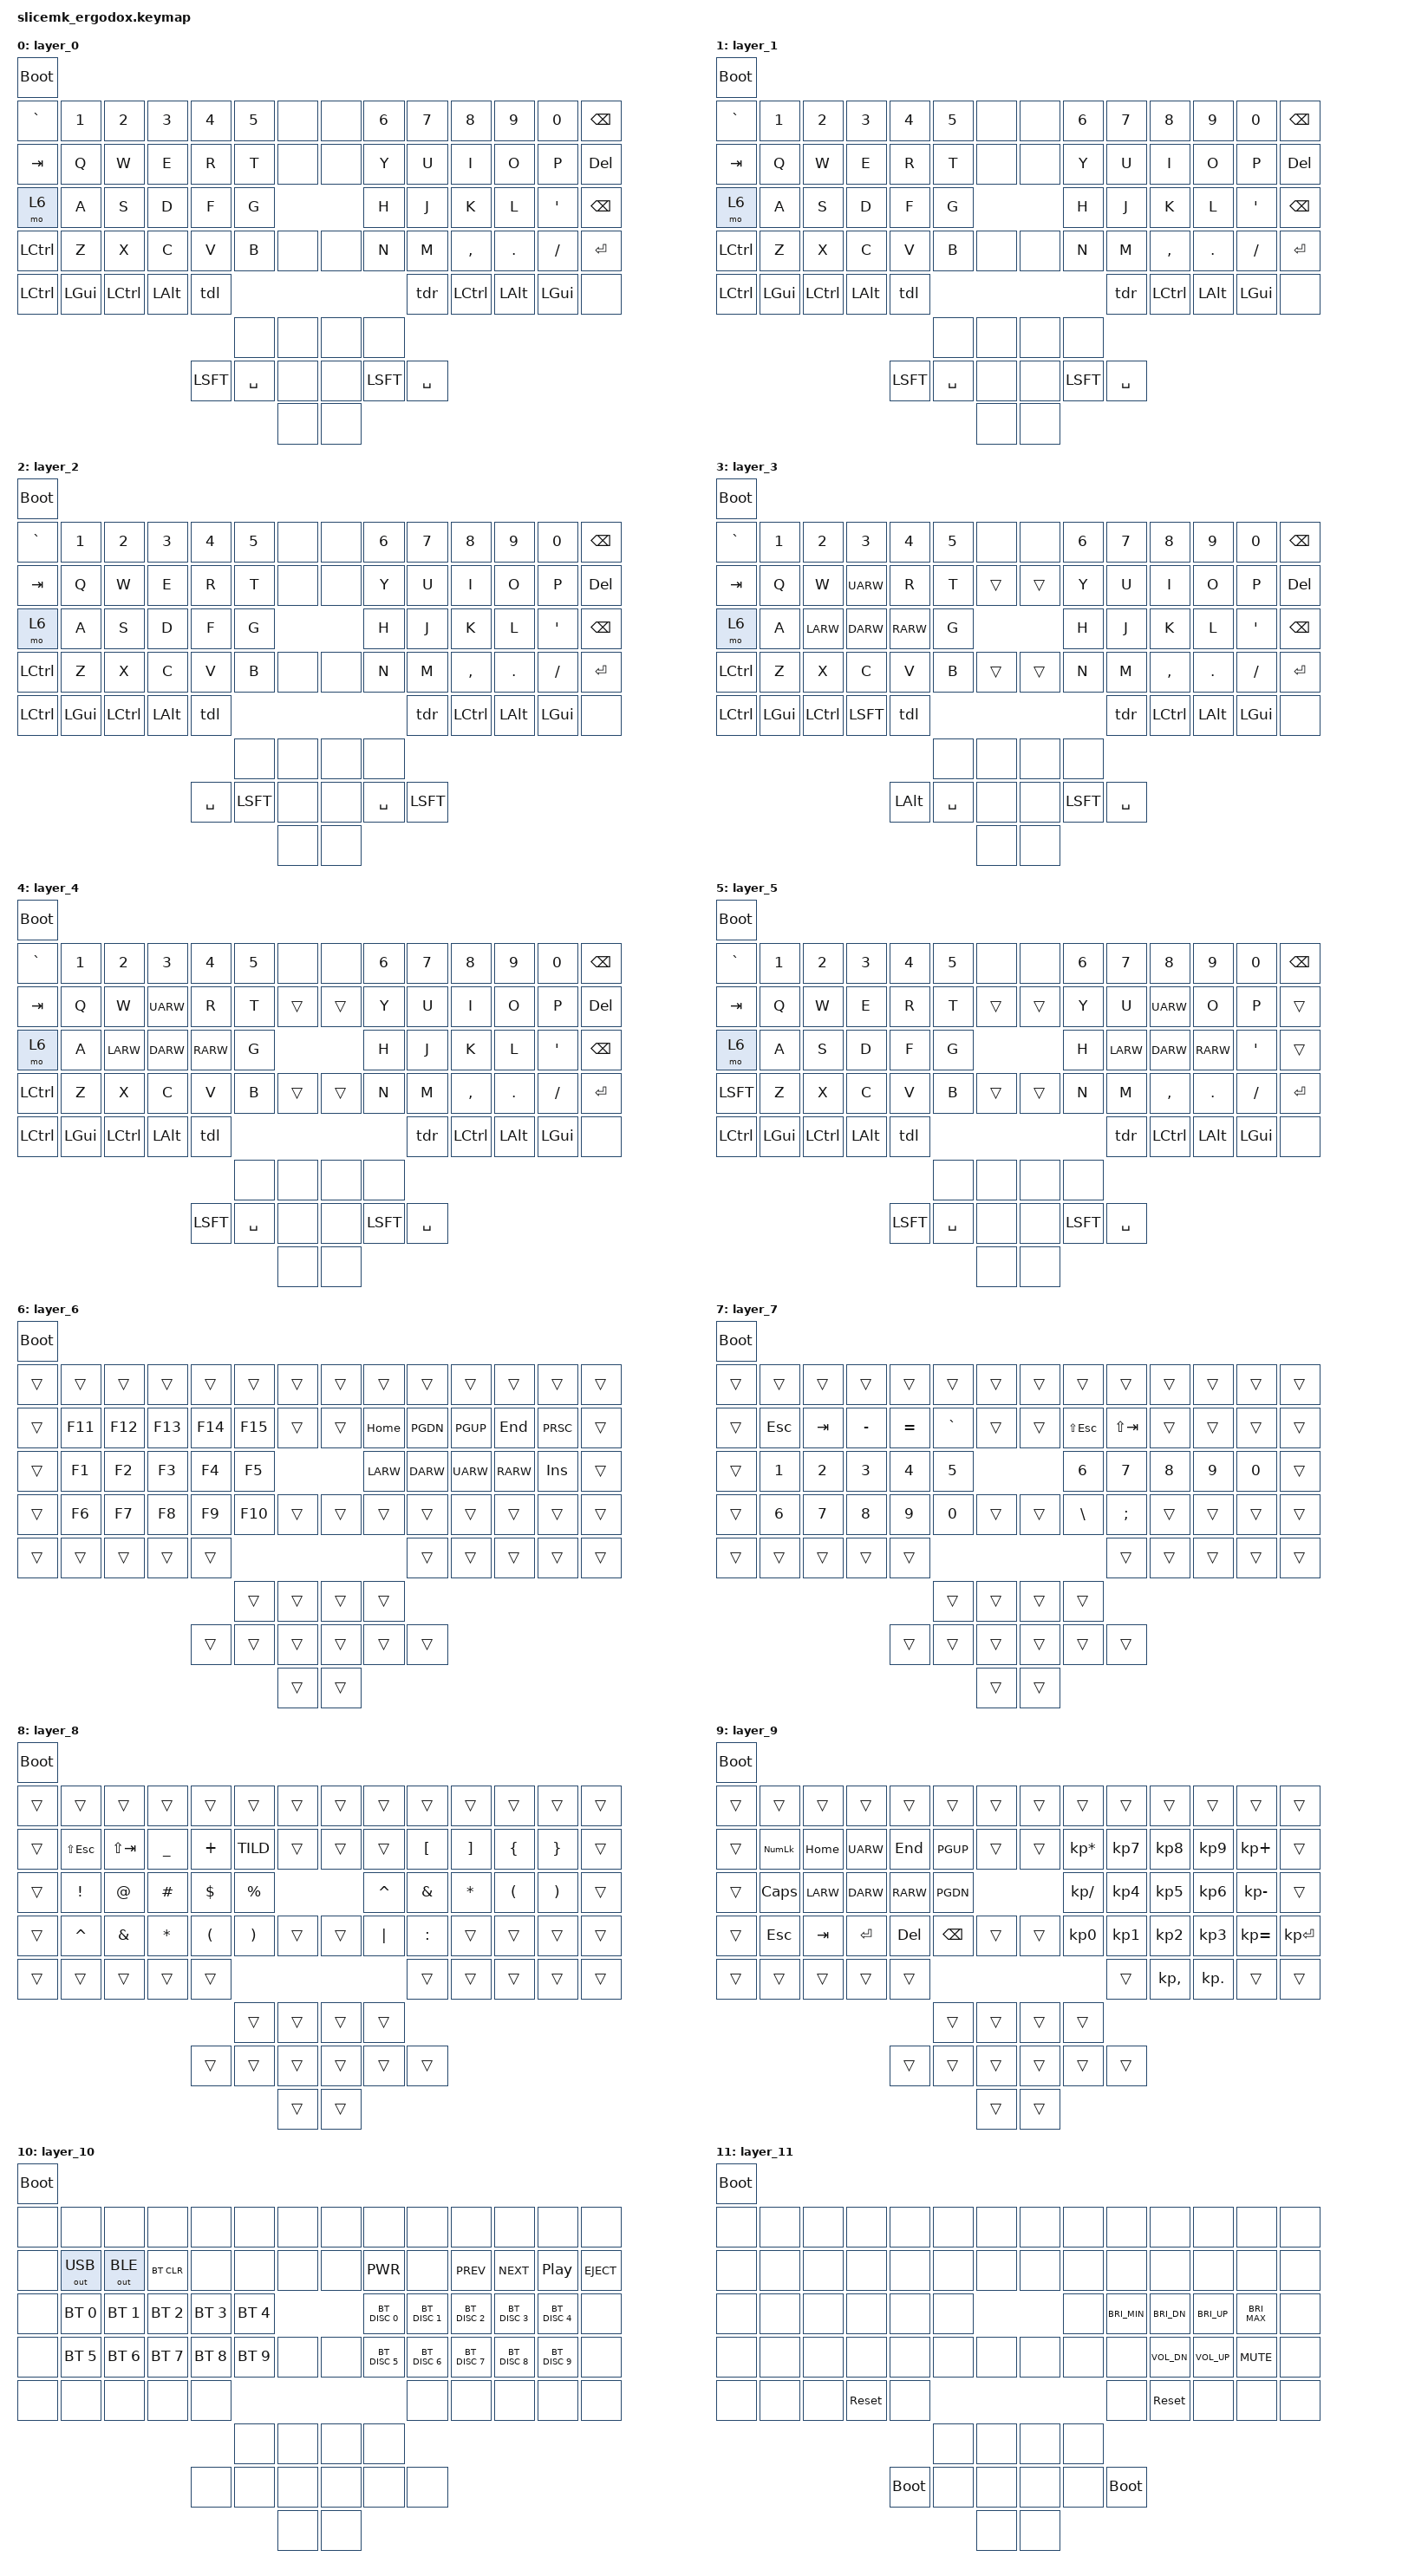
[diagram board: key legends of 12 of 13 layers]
#include <behaviors.dtsi>
#include <dt-bindings/zmk/bt.h>
#include <dt-bindings/zmk/keys.h>
#include <dt-bindings/zmk/outputs.h>

/ {
    combos {
        compatible = "zmk,combos";
        combo_func {
            timeout-ms = <35>;
            key-positions = <59 30>;
            bindings = <&mo 5>;
            slow-release;
        };
        combo_lctl_lower {
            timeout-ms = <35>;
            key-positions = <59 42>;
            bindings = <&kp LCTL>;
            slow-release;
        };
        combo_lshift_lctl {
            timeout-ms = <35>;
            key-positions = <42 60>;
            bindings = <&kp LS(LCTL)>;
            slow-release;
        };
        combo_rshift_rctl {
            timeout-ms = <35>;
            key-positions = <59 61>;
            bindings = <&kp RS(RCTL)>;
            slow-release;
        };
        combo_ralt_raise {
            timeout-ms = <35>;
            key-positions = <60 53>;
            bindings = <&kp RALT>;
            slow-release;
        };
        combo_lshift_lalt {
            timeout-ms = <35>;
            key-positions = <58 60>;
            bindings = <&kp LS(LALT)>;
            slow-release;
        };
        combo_rshift_ralt {
            timeout-ms = <35>;
            key-positions = <59 53>;
            bindings = <&kp RS(RALT)>;
            slow-release;
        };
        combo_lgui_lower {
            timeout-ms = <35>;
            key-positions = <46 59>;
            bindings = <&kp LGUI>;
            slow-release;
        };
        combo_rgui_raise {
            timeout-ms = <35>;
            key-positions = <49 60>;
            bindings = <&kp RS(RGUI)>;
            slow-release;
        };
        combo_ralt {
            timeout-ms = <35>;
            key-positions = <53 60>;
            bindings = <&kp RALT>;
            slow-release;
        };
        combo_lgui {
            timeout-ms = <35>;
            key-positions = <45 46>;
            bindings = <&kp LGUI>;
            layers = <0 6 7 8 9>;
            slow-release;
        };
        combo_rgui {
            timeout-ms = <35>;
            key-positions = <49 50>;
            bindings = <&kp RS(RGUI)>;
            layers = <0 6 7 8 9>;
            slow-release;
        };
        combo_lctl_lalt {
            timeout-ms = <35>;
            key-positions = <42 58>;
            bindings = <&kp LC(LALT)>;
            slow-release;
        };
        combo_rctl_ralt {
            timeout-ms = <35>;
            key-positions = <61 53>;
            bindings = <&kp RC(RALT)>;
            slow-release;
        };
        combo_lalt_tab {
            timeout-ms = <35>;
            key-positions = <16 58>;
            bindings = <&kp LA(TAB)>;
            slow-release;
        };
        combo_lgui_tab {
            timeout-ms = <35>;
            key-positions = <34 46>;
            bindings = <&kp LG(TAB)>;
            slow-release;
        };
        combo_rshift_rgui_tab {
            timeout-ms = <35>;
            key-positions = <35 49>;
            bindings = <&kp RS(RG(TAB))>;
            slow-release;
        };
        combo_layers {
            timeout-ms = <35>;
            key-positions = <59 60>;
            bindings = <&mo 12>;
        };
    };
    behaviors {
        tdl: tap_dance_l {
            compatible = "zmk,behavior-tap-dance";
            label = "TAP_DANCE_L";
            #binding-cells = <0>;
            tapping-term-ms = <400>;
            bindings = <&mo 7>, <&mo 6>, <&mo 10>;
        };
        tdr: tap_dance_r {
            compatible = "zmk,behavior-tap-dance";
            label = "TAP_DANCE_R";
            #binding-cells = <0>;
            tapping-term-ms = <400>;
            bindings = <&mo 8>, <&mo 6>, <&mo 11>;
        };
    };
};

/ {
	keymap {
		compatible = "zmk,keymap";

//				0
//				1  2  3  4  5  6  7  8  9  10 11 12 13 14
//				15 16 17 18 19 20 21 22 23 24 25 26 27 28
//				29 30 31 32 33 34       35 36 37 38 39 40
//				41 42 43 44 45 46 47 48 49 50 51 52 53 54
//				55 56 57 58 59             60 61 62 63 64
//				               65 66 67 68
//				            69 70 71 72 73 74
//				                  75 76

		layer_0 {
			bindings = <
				&bootloader
				&kp GRAV &kp NUMBER_1 &kp NUMBER_2 &kp NUMBER_3 &kp NUMBER_4 &kp NUMBER_5 &none &none &kp NUMBER_6 &kp NUMBER_7 &kp NUMBER_8 &kp NUMBER_9 &kp NUMBER_0 &kp BKSP
				&kp TAB  &kp Q        &kp W        &kp E        &kp R        &kp T        &none &none &kp Y        &kp U        &kp I        &kp O        &kp P        &kp DEL
				&mo 6    &kp A        &kp S        &kp D        &kp F        &kp G                    &kp H        &kp J        &kp K        &kp L        &kp SQT      &kp BKSP
				&kp LCTL &kp Z        &kp X        &kp C        &kp V        &kp B        &none &none &kp N        &kp M        &kp CMMA     &kp DOT      &kp FSLH     &kp RET
				&kp LCTL &kp LGUI     &kp LCTL     &kp LALT     &tdl                                               &tdr         &kp LCTL     &kp LALT     &kp LGUI     &none
				                                                             &none        &none &none &none
				                                                &kp LSFT     &kp SPC      &none &none &kp LSFT     &kp SPC
				                                                                          &none &none
			>;
		};

		layer_1 {
			bindings = <
				&bootloader
				&kp GRAV &kp NUMBER_1 &kp NUMBER_2 &kp NUMBER_3 &kp NUMBER_4 &kp NUMBER_5 &none &none &kp NUMBER_6 &kp NUMBER_7 &kp NUMBER_8 &kp NUMBER_9 &kp NUMBER_0 &kp BKSP
				&kp TAB  &kp Q        &kp W        &kp E        &kp R        &kp T        &none &none &kp Y        &kp U        &kp I        &kp O        &kp P        &kp DEL
				&mo 6    &kp A        &kp S        &kp D        &kp F        &kp G                    &kp H        &kp J        &kp K        &kp L        &kp SQT      &kp BKSP
				&kp LCTL &kp Z        &kp X        &kp C        &kp V        &kp B        &none &none &kp N        &kp M        &kp CMMA     &kp DOT      &kp FSLH     &kp RET
				&kp LCTL &kp LGUI     &kp LCTL     &kp LALT     &tdl                                               &tdr         &kp LCTL     &kp LALT     &kp LGUI     &none
				                                                             &none        &none &none &none
				                                                &kp LSFT     &kp SPC      &none &none &kp LSFT     &kp SPC
				                                                                          &none &none
			>;
		};

		layer_2 {
			bindings = <
				&bootloader
				&kp GRAV &kp NUMBER_1 &kp NUMBER_2 &kp NUMBER_3 &kp NUMBER_4 &kp NUMBER_5 &none &none &kp NUMBER_6 &kp NUMBER_7 &kp NUMBER_8 &kp NUMBER_9 &kp NUMBER_0 &kp BKSP
				&kp TAB  &kp Q        &kp W        &kp E        &kp R        &kp T        &none &none &kp Y        &kp U        &kp I        &kp O        &kp P        &kp DEL
				&mo 6    &kp A        &kp S        &kp D        &kp F        &kp G                    &kp H        &kp J        &kp K        &kp L        &kp SQT      &kp BKSP
				&kp LCTL &kp Z        &kp X        &kp C        &kp V        &kp B        &none &none &kp N        &kp M        &kp CMMA     &kp DOT      &kp FSLH     &kp RET
				&kp LCTL &kp LGUI     &kp LCTL     &kp LALT     &tdl                                               &tdr         &kp LCTL     &kp LALT     &kp LGUI     &none
				                                                             &none        &none &none &none
				                                                &kp SPC      &kp LSFT     &none &none &kp SPC      &kp LSFT
				                                                                          &none &none
			>;
		};

		layer_3 {
			bindings = <
				&bootloader
				&kp GRAV &kp NUMBER_1 &kp NUMBER_2 &kp NUMBER_3 &kp NUMBER_4 &kp NUMBER_5 &none  &none  &kp NUMBER_6 &kp NUMBER_7 &kp NUMBER_8 &kp NUMBER_9 &kp NUMBER_0 &kp BKSP
				&kp TAB  &kp Q        &kp W        &kp UARW     &kp R        &kp T        &trans &trans &kp Y        &kp U        &kp I        &kp O        &kp P        &kp DEL
				&mo 6    &kp A        &kp LARW     &kp DARW     &kp RARW     &kp G                      &kp H        &kp J        &kp K        &kp L        &kp SQT      &kp BKSP
				&kp LCTL &kp Z        &kp X        &kp C        &kp V        &kp B        &trans &trans &kp N        &kp M        &kp CMMA     &kp DOT      &kp FSLH     &kp RET
				&kp LCTL &kp LGUI     &kp LCTL     &kp LSFT     &tdl                                                 &tdr         &kp LCTL     &kp LALT     &kp LGUI     &none
				                                                             &none        &none  &none  &none
				                                                &kp LALT     &kp SPC      &none  &none  &kp LSFT     &kp SPC
				                                                                          &none  &none
			>;
		};

		layer_4 {
			bindings = <
				&bootloader
				&kp GRAV &kp NUMBER_1 &kp NUMBER_2 &kp NUMBER_3 &kp NUMBER_4 &kp NUMBER_5 &none  &none  &kp NUMBER_6 &kp NUMBER_7 &kp NUMBER_8 &kp NUMBER_9 &kp NUMBER_0 &kp BKSP
				&kp TAB  &kp Q        &kp W        &kp UARW     &kp R        &kp T        &trans &trans &kp Y        &kp U        &kp I        &kp O        &kp P        &kp DEL
				&mo 6    &kp A        &kp LARW     &kp DARW     &kp RARW     &kp G                      &kp H        &kp J        &kp K        &kp L        &kp SQT      &kp BKSP
				&kp LCTL &kp Z        &kp X        &kp C        &kp V        &kp B        &trans &trans &kp N        &kp M        &kp CMMA     &kp DOT      &kp FSLH     &kp RET
				&kp LCTL &kp LGUI     &kp LCTL     &kp LALT     &tdl                                                 &tdr         &kp LCTL     &kp LALT     &kp LGUI     &none
				                                                             &none        &none  &none  &none
				                                                &kp LSFT     &kp SPC      &none  &none  &kp LSFT     &kp SPC
				                                                                          &none  &none
			>;
		};

		layer_5 {
			bindings = <
				&bootloader
				&kp GRAV &kp NUMBER_1 &kp NUMBER_2 &kp NUMBER_3 &kp NUMBER_4 &kp NUMBER_5 &none  &none  &kp NUMBER_6 &kp NUMBER_7 &kp NUMBER_8 &kp NUMBER_9 &kp NUMBER_0 &kp BKSP
				&kp TAB  &kp Q        &kp W        &kp E        &kp R        &kp T        &trans &trans &kp Y        &kp U        &kp UARW     &kp O        &kp P        &trans
				&mo 6    &kp A        &kp S        &kp D        &kp F        &kp G                      &kp H        &kp LARW     &kp DARW     &kp RARW     &kp SQT      &trans
				&kp LSFT &kp Z        &kp X        &kp C        &kp V        &kp B        &trans &trans &kp N        &kp M        &kp CMMA     &kp DOT      &kp FSLH     &kp RET
				&kp LCTL &kp LGUI     &kp LCTL     &kp LALT     &tdl                                                 &tdr         &kp LCTL     &kp LALT     &kp LGUI     &none
				                                                             &none        &none  &none  &none
				                                                &kp LSFT     &kp SPC      &none  &none  &kp LSFT     &kp SPC
				                                                                          &none  &none
			>;
		};

		layer_6 {
			bindings = <
				&bootloader
				&trans &trans  &trans  &trans  &trans  &trans   &trans &trans &trans   &trans   &trans   &trans   &trans   &trans
				&trans &kp F11 &kp F12 &kp F13 &kp F14 &kp F15  &trans &trans &kp HOME &kp PGDN &kp PGUP &kp END  &kp PRSC &trans
				&trans &kp F1  &kp F2  &kp F3  &kp F4  &kp F5                 &kp LARW &kp DARW &kp UARW &kp RARW &kp INS  &trans
				&trans &kp F6  &kp F7  &kp F8  &kp F9  &kp F10  &trans &trans &trans   &trans   &trans   &trans   &trans   &trans
				&trans &trans  &trans  &trans  &trans                                  &trans   &trans   &trans   &trans   &trans
				                                       &trans   &trans &trans &trans
				                               &trans  &trans   &trans &trans &trans   &trans
				                                                &trans &trans
			>;
		};

		layer_7 {
			bindings = <
				&bootloader
				&trans &trans       &trans       &trans       &trans       &trans       &trans &trans &trans       &trans       &trans       &trans       &trans       &trans
				&trans &kp ESC      &kp TAB      &kp MINUS    &kp EQUAL    &kp GRAV     &trans &trans &kp LS(ESC)  &kp LS(TAB)  &trans       &trans       &trans       &trans
				&trans &kp NUMBER_1 &kp NUMBER_2 &kp NUMBER_3 &kp NUMBER_4 &kp NUMBER_5               &kp NUMBER_6 &kp NUMBER_7 &kp NUMBER_8 &kp NUMBER_9 &kp NUMBER_0 &trans
				&trans &kp NUMBER_6 &kp NUMBER_7 &kp NUMBER_8 &kp NUMBER_9 &kp NUMBER_0 &trans &trans &kp BSLH     &kp SEMI     &trans       &trans       &trans       &trans
				&trans &trans       &trans       &trans       &trans                                               &trans       &trans       &trans       &trans       &trans
				                                                           &trans       &trans &trans &trans
				                                              &trans       &trans       &trans &trans &trans       &trans
				                                                                        &trans &trans
			>;
		};

		layer_8 {
			bindings = <
				&bootloader
				&trans &trans      &trans      &trans      &trans      &trans    &trans &trans &trans    &trans    &trans   &trans   &trans    &trans
				&trans &kp LS(ESC) &kp LS(TAB) &kp UNDER   &kp PLUS    &kp TILD  &trans &trans &trans    &kp LBKT  &kp RBKT &kp LBRC &kp RBRC  &trans
				&trans &kp EXCL    &kp AT      &kp POUND   &kp DLLR    &kp PRCNT               &kp CARET &kp AMPS  &kp STAR &kp LPAR &kp RPAR  &trans
				&trans &kp CARET   &kp AMPS    &kp STAR    &kp LPAR    &kp RPAR  &trans &trans &kp PIPE  &kp COLON &trans   &trans   &trans    &trans
				&trans &trans      &trans      &trans      &trans                                        &trans    &trans   &trans   &trans    &trans
				                                                       &trans    &trans &trans &trans
				                                           &trans      &trans    &trans &trans &trans    &trans
				                                                                 &trans &trans
			>;
		};

		layer_9 {
			bindings = <
				&bootloader
				&trans &trans      &trans   &trans   &trans   &trans   &trans &trans &trans          &trans    &trans       &trans     &trans       &trans
				&trans &kp KP_NLCK &kp HOME &kp UARW &kp END  &kp PGUP &trans &trans &kp KP_MULTIPLY &kp KP_N7 &kp KP_N8    &kp KP_N9  &kp KP_PLUS  &trans
				&trans &kp CLCK    &kp LARW &kp DARW &kp RARW &kp PGDN               &kp KP_DIVIDE   &kp KP_N4 &kp KP_N5    &kp KP_N6  &kp KP_MINUS &trans
				&trans &kp ESC     &kp TAB  &kp RET  &kp DEL  &kp BKSP &trans &trans &kp KP_N0       &kp KP_N1 &kp KP_N2    &kp KP_N3  &kp KP_EQUAL &kp KP_ENTER
				&trans &trans      &trans   &trans   &trans                                          &trans    &kp KP_COMMA &kp KP_DOT &trans       &trans
				                                              &trans   &trans &trans &trans
				                                     &trans   &trans   &trans &trans &trans          &trans
				                                                       &trans &trans
			>;
		};

		layer_10 {
			bindings = <
				&bootloader
				&none &none        &none        &none        &none        &none        &none &none &none         &none         &none         &none         &none         &none
				&none &out OUT_USB &out OUT_BLE &bt BT_CLR   &none        &none        &none &none &kp C_PWR     &none         &kp C_PREV    &kp C_NEXT    &kp C_PP      &kp C_EJECT
				&none &bt BT_SEL 0 &bt BT_SEL 1 &bt BT_SEL 2 &bt BT_SEL 3 &bt BT_SEL 4             &bt BT_DISC 0 &bt BT_DISC 1 &bt BT_DISC 2 &bt BT_DISC 3 &bt BT_DISC 4 &none
				&none &bt BT_SEL 5 &bt BT_SEL 6 &bt BT_SEL 7 &bt BT_SEL 8 &bt BT_SEL 9 &none &none &bt BT_DISC 5 &bt BT_DISC 6 &bt BT_DISC 7 &bt BT_DISC 8 &bt BT_DISC 9 &none
				&none &none        &none        &none        &none                                               &none         &none         &none         &none         &none
				                                                          &none        &none &none &none
				                                             &none        &none        &none &none &none         &none
				                                                                       &none &none
			>;
		};

		layer_11 {
			bindings = <
				&bootloader
				&none &none &none &none      &none       &none &none &none &none &none         &none        &none        &none         &none
				&none &none &none &none      &none       &none &none &none &none &none         &none        &none        &none         &none
				&none &none &none &none      &none       &none             &none &kp C_BRI_MIN &kp C_BRI_DN &kp C_BRI_UP &kp C_BRI_MAX &none
				&none &none &none &none      &none       &none &none &none &none &none         &kp C_VOL_DN &kp C_VOL_UP &kp C_MUTE    &none
				&none &none &none &sys_reset &none                               &none         &sys_reset   &none        &none         &none
				                                         &none &none &none &none
				                             &bootloader &none &none &none &none &bootloader
				                                               &none &none
			>;
		};

		layer_12 {
			bindings = <
				&bootloader
				&none &none  &none  &none &none &none  &none &none &none &none &none &none &none &none
				&none &to 11 &to 12 &none &none &none  &none &none &none &none &none &none &none &none
				&none &to 1  &to 2  &to 3 &to 4 &to 5              &none &none &none &none &none &none
				&none &to 6  &to 7  &to 8 &to 9 &to 10 &none &none &none &none &none &none &none &none
				&none &none  &none  &none &none                          &none &none &none &none &none
				                                &none  &none &none &none
				                          &to 0 &none  &none &none &none &none
				                                       &none &none
			>;
		};
	};
};
